AUTOSAR XML (schema 4-0-3)
package /ComponentTypes
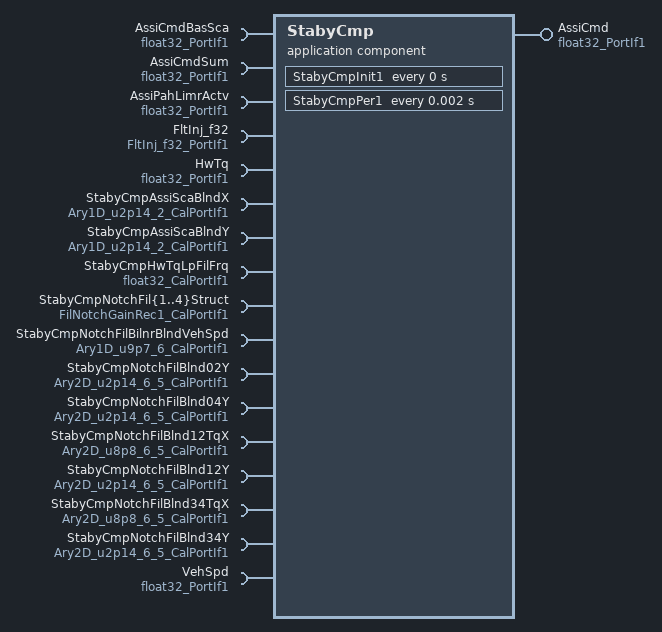
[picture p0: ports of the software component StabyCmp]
  application sw component type StabyCmp
    provide port AssiCmd: nonqueued-sender-com-spec{data-element=Val, init-value=0}, provided-interface=float32_PortIf1
    20 x require port:
      AssiCmdBasSca: nonqueued-receiver-com-spec{data-element=Val, filter=data-filter-type=ALWAYS, init-value=0}, required-interface=float32_PortIf1
      AssiCmdSum: nonqueued-receiver-com-spec{data-element=Val, filter=data-filter-type=ALWAYS, init-value=0}, required-interface=float32_PortIf1
      AssiPahLimrActv: nonqueued-receiver-com-spec{data-element=Val, filter=data-filter-type=ALWAYS, init-value=0}, required-interface=float32_PortIf1
      FltInj_f32: client-com-spec=Oper, required-interface=FltInj_f32_PortIf1
      HwTq: nonqueued-receiver-com-spec{data-element=Val, filter=data-filter-type=ALWAYS, init-value=0}, required-interface=float32_PortIf1
      StabyCmpAssiScaBlndX: parameter-require-com-spec{init-value=[16384, 32768], parameter=Ary1D}, required-interface=Ary1D_u2p14_2_CalPortIf1
      StabyCmpAssiScaBlndY: parameter-require-com-spec{init-value=[0, 0], parameter=Ary1D}, required-interface=Ary1D_u2p14_2_CalPortIf1
      StabyCmpHwTqLpFilFrq: parameter-require-com-spec{init-value=30, parameter=Val}, required-interface=float32_CalPortIf1
      StabyCmpNotchFil{1..4}Struct: parameter-require-com-spec{init-value=fields=[FilGainB0:1, FilGainB1:0, FilGainB2:0, FilGainA1:0, FilGainA2:0], parameter=Rec}, required-interface=FilNotchGainRec1_CalPortIf1
      StabyCmpNotchFilBilnrBlndVehSpd: parameter-require-com-spec{init-value=[0, 1280, 3840, 5760, 7680, 10240], parameter=Ary1D}, required-interface=Ary1D_u9p7_6_CalPortIf1
      StabyCmpNotchFilBlnd02Y: parameter-require-com-spec{init-value=6 x 5 x 16384, parameter=Ary2D}, required-interface=Ary2D_u2p14_6_5_CalPortIf1
      StabyCmpNotchFilBlnd04Y: parameter-require-com-spec{init-value=6 x 5 x 16384, parameter=Ary2D}, required-interface=Ary2D_u2p14_6_5_CalPortIf1
      StabyCmpNotchFilBlnd12TqX: parameter-require-com-spec{init-value=[5 x 0, 5 x 512, 5 x 768, 5 x 1024, 5 x 1536, 5 x 2048], parameter=Ary2D}, required-interface=Ary2D_u8p8_6_5_CalPortIf1
      StabyCmpNotchFilBlnd12Y: parameter-require-com-spec{init-value=6 x 5 x 0, parameter=Ary2D}, required-interface=Ary2D_u2p14_6_5_CalPortIf1
      StabyCmpNotchFilBlnd34TqX: parameter-require-com-spec{init-value=[5 x 0, 5 x 512, 5 x 768, 5 x 1024, 5 x 1536, 5 x 2048], parameter=Ary2D}, required-interface=Ary2D_u8p8_6_5_CalPortIf1
      StabyCmpNotchFilBlnd34Y: parameter-require-com-spec{init-value=6 x 5 x 0, parameter=Ary2D}, required-interface=Ary2D_u2p14_6_5_CalPortIf1
      VehSpd: nonqueued-receiver-com-spec{data-element=Val, filter=data-filter-type=ALWAYS, init-value=0}, required-interface=float32_PortIf1
    behavior StabyCmp_InternalBehavior
      ar-typed-per-instance-memorys:
        16 x data, all with sw-calibration-access=READ-ONLY:
          AssiNotch{1..4}Fil: type=FilNotchStRec1
          dStabyCmpAssiScaCmpBlnd: type=float32
          dStabyCmpNotchFil02Blnd: type=float32
          dStabyCmpNotchFil04Blnd: type=float32
          dStabyCmpNotchFil12Blnd: type=float32
          dStabyCmpNotchFil12Outp: type=float32
          dStabyCmpNotchFil1Outp: type=float32
          dStabyCmpNotchFil2Outp: type=float32
          dStabyCmpNotchFil34Blnd: type=float32
          dStabyCmpNotchFil34Outp: type=float32
          dStabyCmpNotchFil3Outp: type=float32
          dStabyCmpNotchFil4Outp: type=float32
          HwTqLpFil: type=FilLpRec1
      timing event StabyCmp_InitEvent: start-on-event=StabyCmpInit1, period=0
      timing event TMT_StabyCmpPer1: start-on-event=StabyCmpPer1, period=0.002
      runnable StabyCmpInit1
      runnable StabyCmpPer1
        data-receive-point-by-arguments:
          5 x access:
            REC_AssiCmdBasSca_Val: accessed-variable=AssiCmdBasSca.Val
            REC_AssiCmdSum_Val_1: accessed-variable=AssiCmdSum.Val
            REC_AssiPahLimrActv_Val_1: accessed-variable=AssiPahLimrActv.Val
            REC_HwTq_Val_1: accessed-variable=HwTq.Val
            REC_VehSpd_Val_1: accessed-variable=VehSpd.Val
        data-send-points:
          access SEND_AssiCmd_Val_1: accessed-variable=AssiCmd.Val
        sync call SC_FltInj_f32_Oper_1: operation=FltInj_f32.Oper, timeout=0
  swc implementation StabyCmp_Implementation: behavior=StabyCmp_InternalBehavior
    code-descriptors:
      code Default: artifact-descriptors=autosar-engineering-object={short-label=Default, category=SWSRC}
